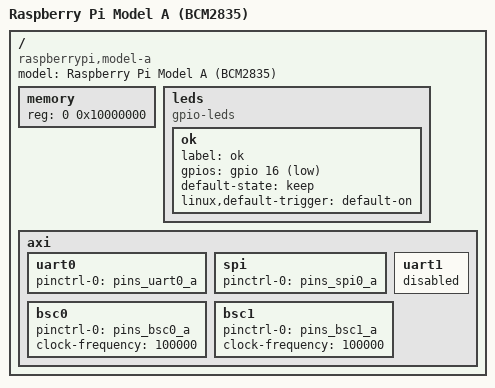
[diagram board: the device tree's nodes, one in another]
/dts-v1/;
/memreserve/ 0x08000000 0x08000000;	/* Set by VideoCore */
/include/ "bcm2835.dtsi"

/ {
	model = "Raspberry Pi Model A (BCM2835)";
	#address-cells = <1>;
	#size-cells = <1>;
	compatible = "raspberrypi,model-a", "broadcom,bcm2835", "broadcom,bcm2708";

	memory {
		device_type = "memory";
		reg = <0 0x10000000>; /* 256MB */
	};

	leds {
		compatible = "gpio-leds";

		ok {
			label = "ok";
			gpios = <&gpio 16 1>;

			/* Don't change this - it configures
			 * how the led driver determines if
			 * the led is on or off when it loads.
			 */
			default-state = "keep";

			/* This is the real default state. */
			linux,default-trigger = "default-on";
		};
	};

	axi {
		uart0 {
			pinctrl-names = "default";
			pinctrl-0 = <&pins_uart0_a>;
		};

		spi {
			pinctrl-names = "default";
			pinctrl-0 = <&pins_spi0_a>;
		};

		bsc0 {
			pinctrl-names = "default";
			pinctrl-0 = <&pins_bsc0_a>;
			clock-frequency = <100000>;
		};

		uart1 {
			status = "disable";
		};

		bsc1 {
			pinctrl-names = "default";
			pinctrl-0 = <&pins_bsc1_a>;
			clock-frequency = <100000>;
		};
	};
};
